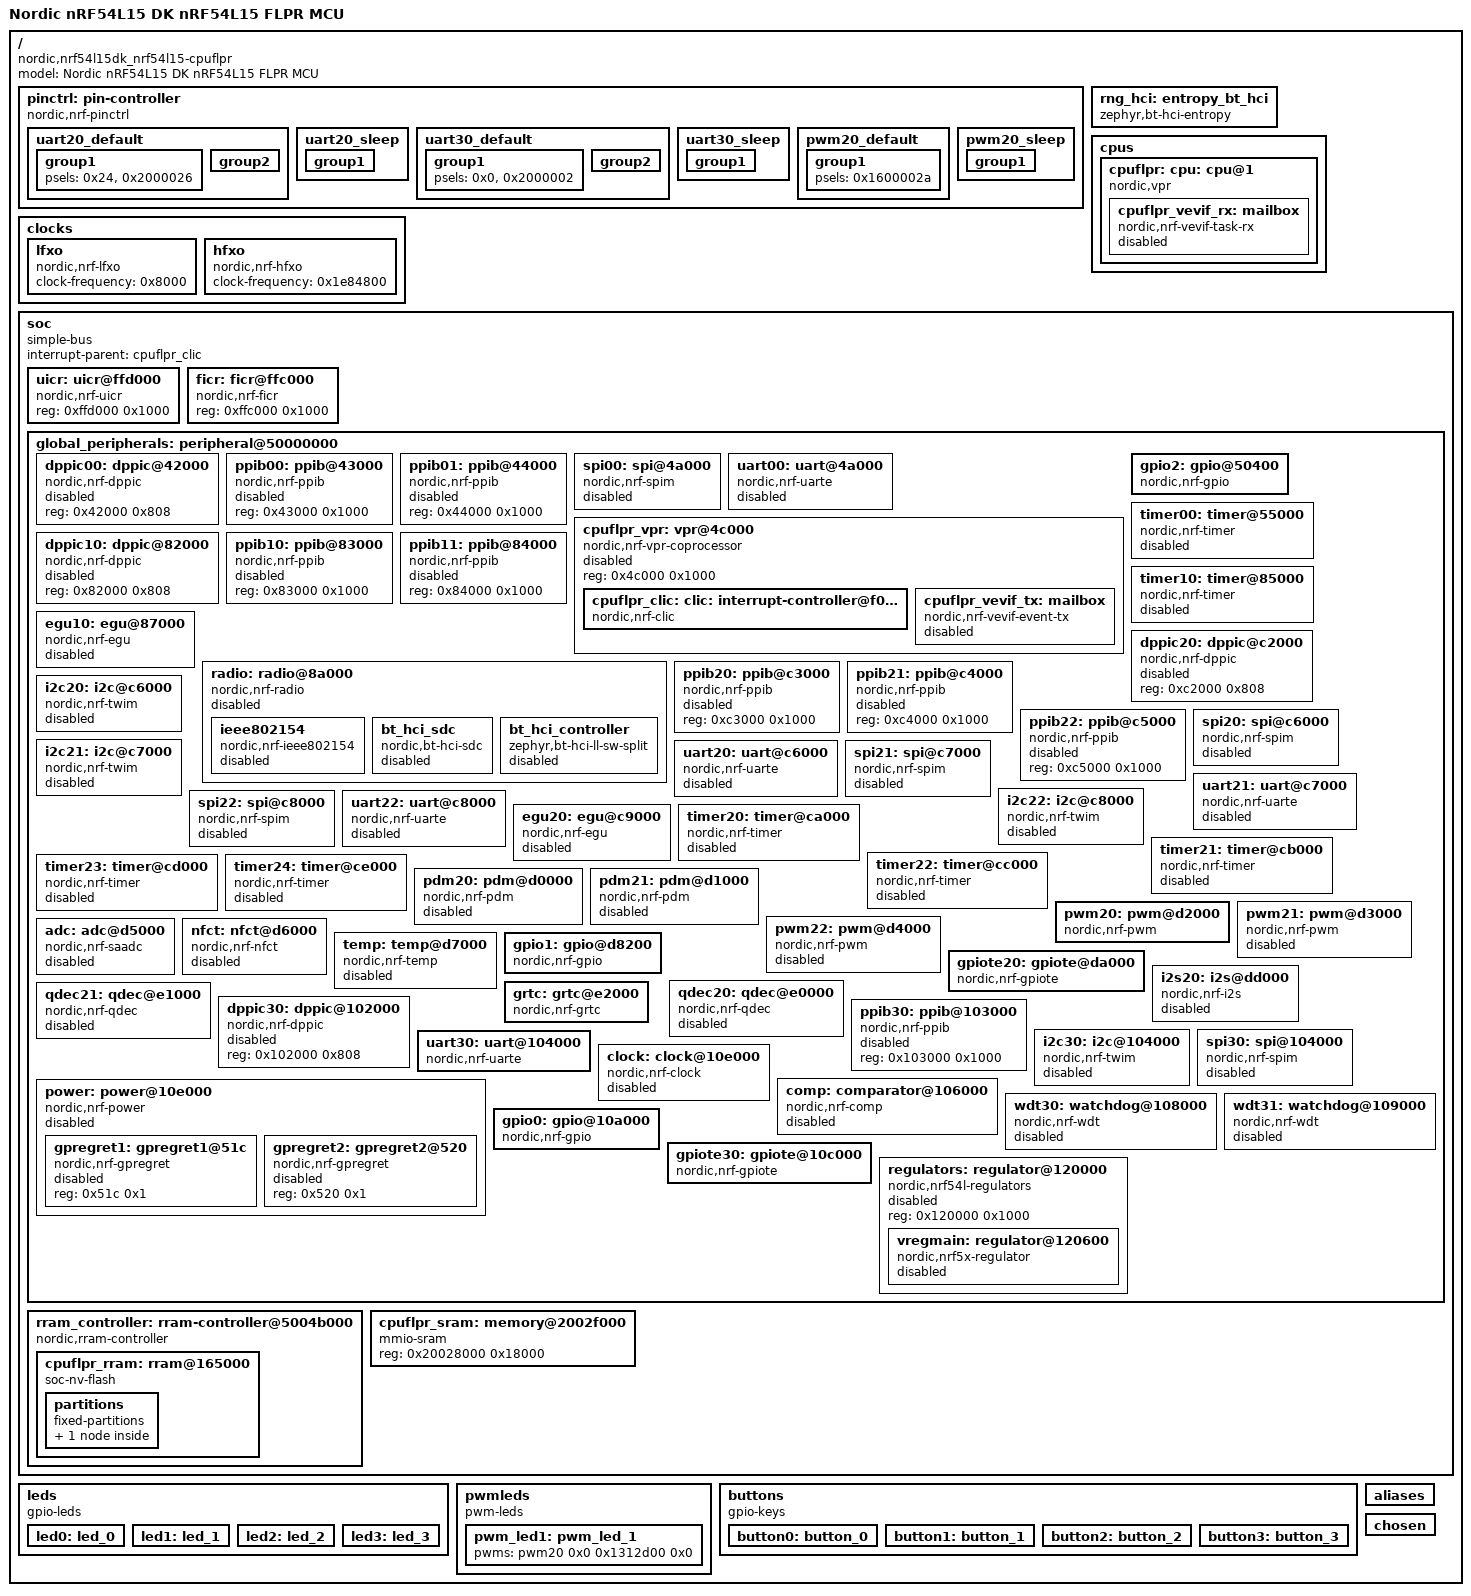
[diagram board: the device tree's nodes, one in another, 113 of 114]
/dts-v1/;

/ {
	#address-cells = < 0x1 >;
	#size-cells = < 0x1 >;
	model = "Nordic nRF54L15 DK nRF54L15 FLPR MCU";
	compatible = "nordic,nrf54l15dk_nrf54l15-cpuflpr";
	pinctrl: pin-controller {
		compatible = "nordic,nrf-pinctrl";
		uart20_default: uart20_default {
			phandle = < 0x2 >;
			group1 {
				psels = < 0x24 >, < 0x2000026 >;
			};
			group2 {
				psels = < 0x1000025 >, < 0x3000027 >;
				bias-pull-up;
			};
		};
		uart20_sleep: uart20_sleep {
			phandle = < 0x3 >;
			group1 {
				psels = < 0x24 >, < 0x1000025 >, < 0x2000026 >, < 0x3000027 >;
				low-power-enable;
			};
		};
		uart30_default: uart30_default {
			phandle = < 0x7 >;
			group1 {
				psels = < 0x0 >, < 0x2000002 >;
			};
			group2 {
				psels = < 0x1000001 >, < 0x3000003 >;
				bias-pull-up;
			};
		};
		uart30_sleep: uart30_sleep {
			phandle = < 0x8 >;
			group1 {
				psels = < 0x0 >, < 0x1000001 >, < 0x2000002 >, < 0x3000003 >;
				low-power-enable;
			};
		};
		pwm20_default: pwm20_default {
			phandle = < 0x4 >;
			group1 {
				psels = < 0x1600002a >;
			};
		};
		pwm20_sleep: pwm20_sleep {
			phandle = < 0x5 >;
			group1 {
				psels = < 0x1600002a >;
				low-power-enable;
			};
		};
	};
	rng_hci: entropy_bt_hci {
		compatible = "zephyr,bt-hci-entropy";
		status = "okay";
	};
	cpus {
		#address-cells = < 0x1 >;
		#size-cells = < 0x0 >;
		cpuflpr: cpu: cpu@1 {
			compatible = "nordic,vpr";
			reg = < 0x1 >;
			device_type = "cpu";
			clock-frequency = < 0x7a12000 >;
			riscv,isa = "rv32emc";
			nordic,bus-width = < 0x20 >;
			cpuflpr_vevif_rx: mailbox {
				compatible = "nordic,nrf-vevif-task-rx";
				status = "disabled";
				interrupt-parent = < &cpuflpr_clic >;
				interrupts = < 0x10 0x1 >, < 0x11 0x1 >, < 0x12 0x1 >, < 0x13 0x1 >, < 0x14 0x1 >, < 0x15 0x1 >, < 0x16 0x1 >;
				#mbox-cells = < 0x1 >;
				nordic,tasks = < 0x7 >;
				nordic,tasks-mask = < 0x7f0000 >;
			};
		};
	};
	clocks {
		lfxo: lfxo {
			compatible = "nordic,nrf-lfxo";
			#clock-cells = < 0x0 >;
			clock-frequency = < 0x8000 >;
		};
		hfxo: hfxo {
			compatible = "nordic,nrf-hfxo";
			#clock-cells = < 0x0 >;
			clock-frequency = < 0x1e84800 >;
		};
	};
	soc {
		#address-cells = < 0x1 >;
		#size-cells = < 0x1 >;
		compatible = "simple-bus";
		interrupt-parent = < &cpuflpr_clic >;
		ranges;
		uicr: uicr@ffd000 {
			compatible = "nordic,nrf-uicr";
			reg = < 0xffd000 0x1000 >;
		};
		ficr: ficr@ffc000 {
			compatible = "nordic,nrf-ficr";
			reg = < 0xffc000 0x1000 >;
			#nordic,ficr-cells = < 0x1 >;
		};
		global_peripherals: peripheral@50000000 {
			#address-cells = < 0x1 >;
			#size-cells = < 0x1 >;
			ranges = < 0x0 0x50000000 0x10000000 >;
			dppic00: dppic@42000 {
				compatible = "nordic,nrf-dppic";
				reg = < 0x42000 0x808 >;
				status = "disabled";
			};
			ppib00: ppib@43000 {
				compatible = "nordic,nrf-ppib";
				reg = < 0x43000 0x1000 >;
				status = "disabled";
			};
			ppib01: ppib@44000 {
				compatible = "nordic,nrf-ppib";
				reg = < 0x44000 0x1000 >;
				status = "disabled";
			};
			spi00: spi@4a000 {
				compatible = "nordic,nrf-spim";
				#address-cells = < 0x1 >;
				#size-cells = < 0x0 >;
				reg = < 0x4a000 0x1000 >;
				interrupts = < 0x4a 0x1 >;
				max-frequency = < 0x1e84800 >;
				easydma-maxcnt-bits = < 0x10 >;
				rx-delay-supported;
				rx-delay = < 0x1 >;
				status = "disabled";
			};
			uart00: uart@4a000 {
				compatible = "nordic,nrf-uarte";
				reg = < 0x4a000 0x1000 >;
				interrupts = < 0x4a 0x1 >;
				status = "disabled";
				endtx-stoptx-supported;
				frame-timeout-supported;
			};
			cpuflpr_vpr: vpr@4c000 {
				compatible = "nordic,nrf-vpr-coprocessor";
				reg = < 0x4c000 0x1000 >;
				ranges = < 0x0 0x4c000 0x1000 >;
				#address-cells = < 0x1 >;
				#size-cells = < 0x1 >;
				status = "disabled";
				cpuflpr_clic: clic: interrupt-controller@f0000000 {
					compatible = "nordic,nrf-clic";
					reg = < 0xf0000000 0x1780 >;
					interrupt-controller;
					#interrupt-cells = < 0x2 >;
					#address-cells = < 0x1 >;
					status = "okay";
					phandle = < 0x1 >;
				};
				cpuflpr_vevif_tx: mailbox {
					compatible = "nordic,nrf-vevif-event-tx";
					#mbox-cells = < 0x1 >;
					nordic,events = < 0x1 >;
					nordic,events-mask = < 0x100000 >;
					status = "disabled";
				};
			};
			gpio2: gpio@50400 {
				compatible = "nordic,nrf-gpio";
				gpio-controller;
				reg = < 0x50400 0x300 >;
				#gpio-cells = < 0x2 >;
				ngpios = < 0xb >;
				status = "okay";
				port = < 0x2 >;
				phandle = < 0xa >;
			};
			timer00: timer@55000 {
				compatible = "nordic,nrf-timer";
				status = "disabled";
				reg = < 0x55000 0x1000 >;
				cc-num = < 0x6 >;
				max-bit-width = < 0x20 >;
				interrupts = < 0x55 0x1 >;
				max-frequency = < 0x7a12000 >;
				prescaler = < 0x0 >;
			};
			dppic10: dppic@82000 {
				compatible = "nordic,nrf-dppic";
				reg = < 0x82000 0x808 >;
				status = "disabled";
			};
			ppib10: ppib@83000 {
				compatible = "nordic,nrf-ppib";
				reg = < 0x83000 0x1000 >;
				status = "disabled";
			};
			ppib11: ppib@84000 {
				compatible = "nordic,nrf-ppib";
				reg = < 0x84000 0x1000 >;
				status = "disabled";
			};
			timer10: timer@85000 {
				compatible = "nordic,nrf-timer";
				status = "disabled";
				reg = < 0x85000 0x1000 >;
				cc-num = < 0x8 >;
				max-bit-width = < 0x20 >;
				interrupts = < 0x85 0x1 >;
				max-frequency = < 0x1e84800 >;
				prescaler = < 0x0 >;
			};
			egu10: egu@87000 {
				compatible = "nordic,nrf-egu";
				reg = < 0x87000 0x1000 >;
				interrupts = < 0x87 0x1 >;
				status = "disabled";
			};
			radio: radio@8a000 {
				compatible = "nordic,nrf-radio";
				reg = < 0x8a000 0x1000 >;
				interrupts = < 0x8a 0x1 >;
				status = "disabled";
				dfe-supported;
				ieee802154-supported;
				ble-2mbps-supported;
				ble-coded-phy-supported;
				cs-supported;
				ieee802154: ieee802154 {
					compatible = "nordic,nrf-ieee802154";
					status = "disabled";
				};
				bt_hci_sdc: bt_hci_sdc {
					compatible = "nordic,bt-hci-sdc";
					status = "disabled";
				};
				bt_hci_controller: bt_hci_controller {
					compatible = "zephyr,bt-hci-ll-sw-split";
					status = "disabled";
				};
			};
			dppic20: dppic@c2000 {
				compatible = "nordic,nrf-dppic";
				reg = < 0xc2000 0x808 >;
				status = "disabled";
			};
			ppib20: ppib@c3000 {
				compatible = "nordic,nrf-ppib";
				reg = < 0xc3000 0x1000 >;
				status = "disabled";
			};
			ppib21: ppib@c4000 {
				compatible = "nordic,nrf-ppib";
				reg = < 0xc4000 0x1000 >;
				status = "disabled";
			};
			ppib22: ppib@c5000 {
				compatible = "nordic,nrf-ppib";
				reg = < 0xc5000 0x1000 >;
				status = "disabled";
			};
			i2c20: i2c@c6000 {
				compatible = "nordic,nrf-twim";
				#address-cells = < 0x1 >;
				#size-cells = < 0x0 >;
				reg = < 0xc6000 0x1000 >;
				interrupts = < 0xc6 0x1 >;
				easydma-maxcnt-bits = < 0x10 >;
				status = "disabled";
				zephyr,pm-device-runtime-auto;
			};
			spi20: spi@c6000 {
				compatible = "nordic,nrf-spim";
				#address-cells = < 0x1 >;
				#size-cells = < 0x0 >;
				reg = < 0xc6000 0x1000 >;
				interrupts = < 0xc6 0x1 >;
				max-frequency = < 0x7a1200 >;
				easydma-maxcnt-bits = < 0x10 >;
				rx-delay-supported;
				rx-delay = < 0x1 >;
				status = "disabled";
			};
			uart20: uart@c6000 {
				compatible = "nordic,nrf-uarte";
				reg = < 0xc6000 0x1000 >;
				interrupts = < 0xc6 0x1 >;
				status = "disabled";
				endtx-stoptx-supported;
				frame-timeout-supported;
				current-speed = < 0x1c200 >;
				pinctrl-0 = < &uart20_default >;
				pinctrl-1 = < &uart20_sleep >;
				pinctrl-names = "default", "sleep";
			};
			i2c21: i2c@c7000 {
				compatible = "nordic,nrf-twim";
				#address-cells = < 0x1 >;
				#size-cells = < 0x0 >;
				reg = < 0xc7000 0x1000 >;
				interrupts = < 0xc7 0x1 >;
				easydma-maxcnt-bits = < 0x10 >;
				status = "disabled";
				zephyr,pm-device-runtime-auto;
			};
			spi21: spi@c7000 {
				compatible = "nordic,nrf-spim";
				#address-cells = < 0x1 >;
				#size-cells = < 0x0 >;
				reg = < 0xc7000 0x1000 >;
				interrupts = < 0xc7 0x1 >;
				max-frequency = < 0x7a1200 >;
				easydma-maxcnt-bits = < 0x10 >;
				rx-delay-supported;
				rx-delay = < 0x1 >;
				status = "disabled";
			};
			uart21: uart@c7000 {
				compatible = "nordic,nrf-uarte";
				reg = < 0xc7000 0x1000 >;
				interrupts = < 0xc7 0x1 >;
				status = "disabled";
				endtx-stoptx-supported;
				frame-timeout-supported;
			};
			i2c22: i2c@c8000 {
				compatible = "nordic,nrf-twim";
				#address-cells = < 0x1 >;
				#size-cells = < 0x0 >;
				reg = < 0xc8000 0x1000 >;
				interrupts = < 0xc8 0x1 >;
				easydma-maxcnt-bits = < 0x10 >;
				status = "disabled";
				zephyr,pm-device-runtime-auto;
			};
			spi22: spi@c8000 {
				compatible = "nordic,nrf-spim";
				#address-cells = < 0x1 >;
				#size-cells = < 0x0 >;
				reg = < 0xc8000 0x1000 >;
				interrupts = < 0xc8 0x1 >;
				max-frequency = < 0x7a1200 >;
				easydma-maxcnt-bits = < 0x10 >;
				rx-delay-supported;
				rx-delay = < 0x1 >;
				status = "disabled";
			};
			uart22: uart@c8000 {
				compatible = "nordic,nrf-uarte";
				reg = < 0xc8000 0x1000 >;
				interrupts = < 0xc8 0x1 >;
				status = "disabled";
				endtx-stoptx-supported;
				frame-timeout-supported;
			};
			egu20: egu@c9000 {
				compatible = "nordic,nrf-egu";
				reg = < 0xc9000 0x1000 >;
				interrupts = < 0xc9 0x1 >;
				status = "disabled";
			};
			timer20: timer@ca000 {
				compatible = "nordic,nrf-timer";
				status = "disabled";
				reg = < 0xca000 0x1000 >;
				cc-num = < 0x6 >;
				max-bit-width = < 0x20 >;
				interrupts = < 0xca 0x1 >;
				prescaler = < 0x0 >;
			};
			timer21: timer@cb000 {
				compatible = "nordic,nrf-timer";
				status = "disabled";
				reg = < 0xcb000 0x1000 >;
				cc-num = < 0x6 >;
				max-bit-width = < 0x20 >;
				interrupts = < 0xcb 0x1 >;
				prescaler = < 0x0 >;
			};
			timer22: timer@cc000 {
				compatible = "nordic,nrf-timer";
				status = "disabled";
				reg = < 0xcc000 0x1000 >;
				cc-num = < 0x6 >;
				max-bit-width = < 0x20 >;
				interrupts = < 0xcc 0x1 >;
				prescaler = < 0x0 >;
			};
			timer23: timer@cd000 {
				compatible = "nordic,nrf-timer";
				status = "disabled";
				reg = < 0xcd000 0x1000 >;
				cc-num = < 0x6 >;
				max-bit-width = < 0x20 >;
				interrupts = < 0xcd 0x1 >;
				prescaler = < 0x0 >;
			};
			timer24: timer@ce000 {
				compatible = "nordic,nrf-timer";
				status = "disabled";
				reg = < 0xce000 0x1000 >;
				cc-num = < 0x6 >;
				max-bit-width = < 0x20 >;
				interrupts = < 0xce 0x1 >;
				prescaler = < 0x0 >;
			};
			pdm20: pdm@d0000 {
				compatible = "nordic,nrf-pdm";
				status = "disabled";
				reg = < 0xd0000 0x1000 >;
				interrupts = < 0xd0 0x1 >;
			};
			pdm21: pdm@d1000 {
				compatible = "nordic,nrf-pdm";
				status = "disabled";
				reg = < 0xd1000 0x1000 >;
				interrupts = < 0xd1 0x1 >;
			};
			pwm20: pwm@d2000 {
				compatible = "nordic,nrf-pwm";
				status = "okay";
				reg = < 0xd2000 0x1000 >;
				interrupts = < 0xd2 0x1 >;
				#pwm-cells = < 0x3 >;
				pinctrl-0 = < &pwm20_default >;
				pinctrl-1 = < &pwm20_sleep >;
				pinctrl-names = "default", "sleep";
				phandle = < 0xc >;
			};
			pwm21: pwm@d3000 {
				compatible = "nordic,nrf-pwm";
				status = "disabled";
				reg = < 0xd3000 0x1000 >;
				interrupts = < 0xd3 0x1 >;
				#pwm-cells = < 0x3 >;
			};
			pwm22: pwm@d4000 {
				compatible = "nordic,nrf-pwm";
				status = "disabled";
				reg = < 0xd4000 0x1000 >;
				interrupts = < 0xd4 0x1 >;
				#pwm-cells = < 0x3 >;
			};
			adc: adc@d5000 {
				compatible = "nordic,nrf-saadc";
				reg = < 0xd5000 0x1000 >;
				interrupts = < 0xd5 0x1 >;
				status = "disabled";
				#io-channel-cells = < 0x1 >;
			};
			nfct: nfct@d6000 {
				compatible = "nordic,nrf-nfct";
				reg = < 0xd6000 0x1000 >;
				interrupts = < 0xd6 0x1 >;
				status = "disabled";
			};
			temp: temp@d7000 {
				compatible = "nordic,nrf-temp";
				reg = < 0xd7000 0x1000 >;
				interrupts = < 0xd7 0x1 >;
				status = "disabled";
			};
			gpio1: gpio@d8200 {
				compatible = "nordic,nrf-gpio";
				gpio-controller;
				reg = < 0xd8200 0x300 >;
				#gpio-cells = < 0x2 >;
				ngpios = < 0x10 >;
				status = "okay";
				port = < 0x1 >;
				gpiote-instance = < &gpiote20 >;
				phandle = < 0xb >;
			};
			gpiote20: gpiote@da000 {
				compatible = "nordic,nrf-gpiote";
				reg = < 0xda000 0x1000 >;
				status = "okay";
				instance = < 0x14 >;
				interrupts = < 0xda 0x1 >;
				phandle = < 0x6 >;
			};
			i2s20: i2s@dd000 {
				compatible = "nordic,nrf-i2s";
				#address-cells = < 0x1 >;
				#size-cells = < 0x0 >;
				reg = < 0xdd000 0x1000 >;
				interrupts = < 0xdd 0x1 >;
				status = "disabled";
			};
			qdec20: qdec@e0000 {
				compatible = "nordic,nrf-qdec";
				reg = < 0xe0000 0x1000 >;
				interrupts = < 0xe0 0x1 >;
				status = "disabled";
			};
			qdec21: qdec@e1000 {
				compatible = "nordic,nrf-qdec";
				reg = < 0xe1000 0x1000 >;
				interrupts = < 0xe1 0x1 >;
				status = "disabled";
			};
			grtc: grtc@e2000 {
				compatible = "nordic,nrf-grtc";
				reg = < 0xe2000 0x1000 >;
				cc-num = < 0xc >;
				status = "okay";
				interrupts = < 0xe2 0x1 >;
				owned-channels = < 0x3 0x4 >;
			};
			dppic30: dppic@102000 {
				compatible = "nordic,nrf-dppic";
				reg = < 0x102000 0x808 >;
				status = "disabled";
			};
			ppib30: ppib@103000 {
				compatible = "nordic,nrf-ppib";
				reg = < 0x103000 0x1000 >;
				status = "disabled";
			};
			i2c30: i2c@104000 {
				compatible = "nordic,nrf-twim";
				#address-cells = < 0x1 >;
				#size-cells = < 0x0 >;
				reg = < 0x104000 0x1000 >;
				interrupts = < 0x104 0x1 >;
				easydma-maxcnt-bits = < 0x10 >;
				status = "disabled";
				zephyr,pm-device-runtime-auto;
			};
			spi30: spi@104000 {
				compatible = "nordic,nrf-spim";
				#address-cells = < 0x1 >;
				#size-cells = < 0x0 >;
				reg = < 0x104000 0x1000 >;
				interrupts = < 0x104 0x1 >;
				max-frequency = < 0x7a1200 >;
				easydma-maxcnt-bits = < 0x10 >;
				rx-delay-supported;
				rx-delay = < 0x1 >;
				status = "disabled";
			};
			uart30: uart@104000 {
				compatible = "nordic,nrf-uarte";
				reg = < 0x104000 0x1000 >;
				interrupts = < 0x104 0x1 >;
				status = "okay";
				endtx-stoptx-supported;
				frame-timeout-supported;
				current-speed = < 0x1c200 >;
				pinctrl-0 = < &uart30_default >;
				pinctrl-1 = < &uart30_sleep >;
				pinctrl-names = "default", "sleep";
			};
			clock: clock@10e000 {
				compatible = "nordic,nrf-clock";
				reg = < 0x10e000 0x1000 >;
				interrupts = < 0x105 0x1 >;
				status = "disabled";
			};
			power: power@10e000 {
				compatible = "nordic,nrf-power";
				reg = < 0x10e000 0x1000 >;
				ranges = < 0x0 0x10e000 0x1000 >;
				interrupts = < 0x105 0x1 >;
				status = "disabled";
				#address-cells = < 0x1 >;
				#size-cells = < 0x1 >;
				gpregret1: gpregret1@51c {
					#address-cells = < 0x1 >;
					#size-cells = < 0x1 >;
					compatible = "nordic,nrf-gpregret";
					reg = < 0x51c 0x1 >;
					status = "disabled";
				};
				gpregret2: gpregret2@520 {
					#address-cells = < 0x1 >;
					#size-cells = < 0x1 >;
					compatible = "nordic,nrf-gpregret";
					reg = < 0x520 0x1 >;
					status = "disabled";
				};
			};
			comp: comparator@106000 {
				compatible = "nordic,nrf-comp";
				reg = < 0x106000 0x1000 >;
				status = "disabled";
				interrupts = < 0x106 0x1 >;
			};
			wdt30: watchdog@108000 {
				compatible = "nordic,nrf-wdt";
				reg = < 0x108000 0x620 >;
				interrupts = < 0x108 0x1 >;
				status = "disabled";
			};
			wdt31: watchdog@109000 {
				compatible = "nordic,nrf-wdt";
				reg = < 0x109000 0x620 >;
				interrupts = < 0x109 0x1 >;
				status = "disabled";
			};
			gpio0: gpio@10a000 {
				compatible = "nordic,nrf-gpio";
				gpio-controller;
				reg = < 0x10a000 0x300 >;
				#gpio-cells = < 0x2 >;
				ngpios = < 0x5 >;
				status = "okay";
				port = < 0x0 >;
				gpiote-instance = < &gpiote30 >;
				phandle = < 0xd >;
			};
			gpiote30: gpiote@10c000 {
				compatible = "nordic,nrf-gpiote";
				reg = < 0x10c000 0x1000 >;
				status = "okay";
				instance = < 0x1e >;
				interrupts = < 0x10c 0x1 >;
				phandle = < 0x9 >;
			};
			regulators: regulator@120000 {
				compatible = "nordic,nrf54l-regulators";
				reg = < 0x120000 0x1000 >;
				status = "disabled";
				#address-cells = < 0x1 >;
				#size-cells = < 0x1 >;
				vregmain: regulator@120600 {
					compatible = "nordic,nrf5x-regulator";
					reg = < 0x120600 0x1 >;
					status = "disabled";
					regulator-name = "VREGMAIN";
					regulator-initial-mode = < 0x0 >;
				};
			};
		};
		rram_controller: rram-controller@5004b000 {
			compatible = "nordic,rram-controller";
			reg = < 0x5004b000 0x1000 >;
			#address-cells = < 0x1 >;
			#size-cells = < 0x1 >;
			interrupts = < 0x4b 0x1 >;
			cpuflpr_rram: rram@165000 {
				compatible = "soc-nv-flash";
				reg = < 0x165000 0x18000 >;
				erase-block-size = < 0x1000 >;
				write-block-size = < 0x10 >;
				partitions {
					compatible = "fixed-partitions";
					#address-cells = < 0x1 >;
					#size-cells = < 0x1 >;
					cpuflpr_code_partition: partition@0 {
						label = "image-0";
						reg = < 0x0 0x18000 >;
					};
				};
			};
		};
		cpuflpr_sram: memory@2002f000 {
			compatible = "mmio-sram";
			reg = < 0x20028000 0x18000 >;
			#address-cells = < 0x1 >;
			#size-cells = < 0x1 >;
			ranges = < 0x0 0x20028000 0x18000 >;
			status = "okay";
		};
	};
	leds {
		compatible = "gpio-leds";
		led0: led_0 {
			gpios = < &gpio2 0x9 0x0 >;
			label = "Green LED 0";
		};
		led1: led_1 {
			gpios = < &gpio1 0xa 0x0 >;
			label = "Green LED 1";
		};
		led2: led_2 {
			gpios = < &gpio2 0x7 0x0 >;
			label = "Green LED 2";
		};
		led3: led_3 {
			gpios = < &gpio1 0xe 0x0 >;
			label = "Green LED 3";
		};
	};
	pwmleds {
		compatible = "pwm-leds";
		pwm_led1: pwm_led_1 {
			pwms = < &pwm20 0x0 0x1312d00 0x0 >;
		};
	};
	buttons {
		compatible = "gpio-keys";
		button0: button_0 {
			gpios = < &gpio1 0xd 0x11 >;
			label = "Push button 0";
			zephyr,code = < 0xb >;
		};
		button1: button_1 {
			gpios = < &gpio1 0x9 0x11 >;
			label = "Push button 1";
			zephyr,code = < 0x2 >;
		};
		button2: button_2 {
			gpios = < &gpio1 0x8 0x11 >;
			label = "Push button 2";
			zephyr,code = < 0x3 >;
		};
		button3: button_3 {
			gpios = < &gpio0 0x4 0x11 >;
			label = "Push button 3";
			zephyr,code = < 0x4 >;
		};
	};
	aliases {
		led0 = &led0;
		led1 = &led1;
		led2 = &led2;
		led3 = &led3;
		pwm-led0 = &pwm_led1;
		sw0 = &button0;
		sw1 = &button1;
		sw2 = &button2;
		sw3 = &button3;
		watchdog0 = &wdt31;
	};
	chosen {
		zephyr,console = &uart30;
		zephyr,shell-uart = &uart30;
		zephyr,code-partition = &cpuflpr_code_partition;
		zephyr,flash = &cpuflpr_rram;
		zephyr,sram = &cpuflpr_sram;
	};
};
